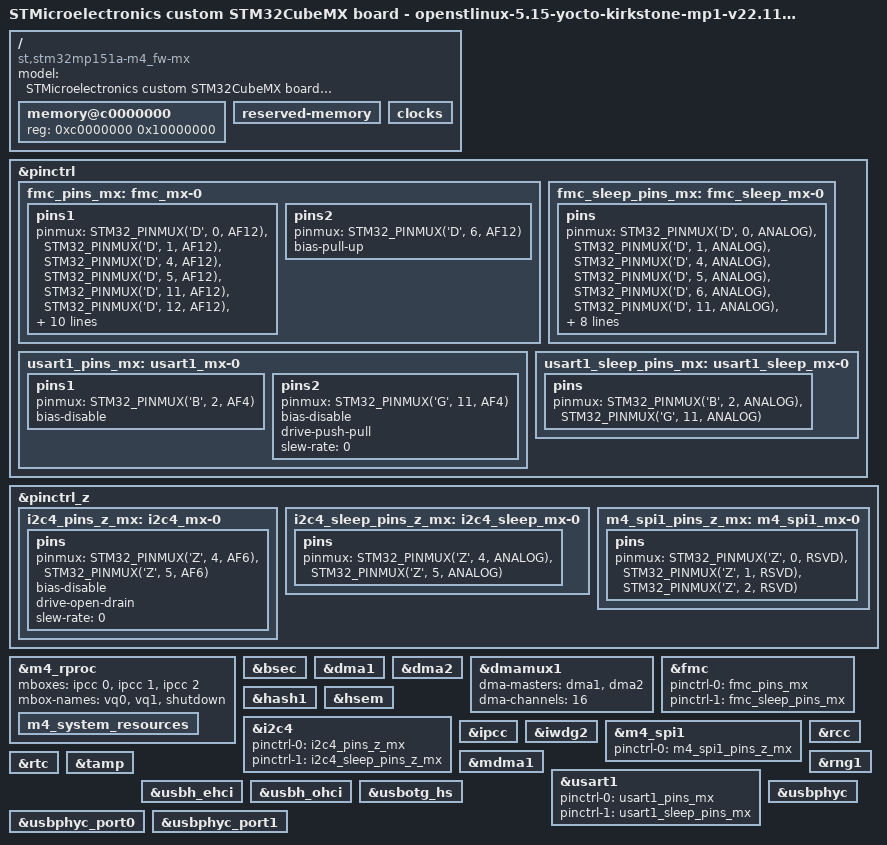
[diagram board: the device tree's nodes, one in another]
/* SPDX-License-Identifier: (GPL-2.0+ OR BSD-3-Clause) */
/*
 * Copyright (C) STMicroelectronics 2023 - All Rights Reserved
 * Author: STM32CubeMX code generation for STMicroelectronics.
 */

/* For more information on Device Tree configuration, please refer to
 * https://wiki.st.com/stm32mpu/wiki/Category:Device_tree_configuration
 */

/dts-v1/;
#include <dt-bindings/pinctrl/stm32-pinfunc.h>

#include "stm32mp151.dtsi"
#include "stm32mp15xa.dtsi"
#include "stm32mp15xxac-pinctrl.dtsi"
#include "stm32mp15-m4-srm.dtsi"

/* USER CODE BEGIN includes */
/* USER CODE END includes */

/ {
	model = "STMicroelectronics custom STM32CubeMX board - openstlinux-5.15-yocto-kirkstone-mp1-v22.11.23";
	compatible = "st,stm32mp151a-m4_fw-mx", "st,stm32mp151";

	memory@c0000000 {
		device_type = "memory";
		reg = <0xc0000000 0x10000000>;

		/* USER CODE BEGIN memory */
		/* USER CODE END memory */
	};

	reserved-memory {
		#address-cells = <1>;
		#size-cells = <1>;
		ranges;

		/* USER CODE BEGIN reserved-memory */
		/* USER CODE END reserved-memory */
	};

	/* USER CODE BEGIN root */
	/* USER CODE END root */

	clocks {

		/* USER CODE BEGIN clocks */
		/* USER CODE END clocks */
	};

}; /*root*/

&pinctrl {

	fmc_pins_mx: fmc_mx-0 {
		pins1 {
			pinmux = <STM32_PINMUX('D', 0, AF12)>, /* FMC_D2 */
					 <STM32_PINMUX('D', 1, AF12)>, /* FMC_D3 */
					 <STM32_PINMUX('D', 4, AF12)>, /* FMC_NOE */
					 <STM32_PINMUX('D', 5, AF12)>, /* FMC_NWE */
					 <STM32_PINMUX('D', 11, AF12)>, /* FMC_CLE */
					 <STM32_PINMUX('D', 12, AF12)>, /* FMC_ALE */
					 <STM32_PINMUX('D', 14, AF12)>, /* FMC_D0 */
					 <STM32_PINMUX('D', 15, AF12)>, /* FMC_D1 */
					 <STM32_PINMUX('E', 7, AF12)>, /* FMC_D4 */
					 <STM32_PINMUX('E', 8, AF12)>, /* FMC_D5 */
					 <STM32_PINMUX('E', 9, AF12)>, /* FMC_D6 */
					 <STM32_PINMUX('E', 10, AF12)>, /* FMC_D7 */
					 <STM32_PINMUX('G', 9, AF12)>; /* FMC_NCE */
			bias-disable;
			drive-push-pull;
			slew-rate = <1>;
		};
		pins2 {
			pinmux = <STM32_PINMUX('D', 6, AF12)>; /* FMC_NWAIT */
			bias-pull-up;
		};
	};

	fmc_sleep_pins_mx: fmc_sleep_mx-0 {
		pins {
			pinmux = <STM32_PINMUX('D', 0, ANALOG)>, /* FMC_D2 */
					 <STM32_PINMUX('D', 1, ANALOG)>, /* FMC_D3 */
					 <STM32_PINMUX('D', 4, ANALOG)>, /* FMC_NOE */
					 <STM32_PINMUX('D', 5, ANALOG)>, /* FMC_NWE */
					 <STM32_PINMUX('D', 6, ANALOG)>, /* FMC_NWAIT */
					 <STM32_PINMUX('D', 11, ANALOG)>, /* FMC_CLE */
					 <STM32_PINMUX('D', 12, ANALOG)>, /* FMC_ALE */
					 <STM32_PINMUX('D', 14, ANALOG)>, /* FMC_D0 */
					 <STM32_PINMUX('D', 15, ANALOG)>, /* FMC_D1 */
					 <STM32_PINMUX('E', 7, ANALOG)>, /* FMC_D4 */
					 <STM32_PINMUX('E', 8, ANALOG)>, /* FMC_D5 */
					 <STM32_PINMUX('E', 9, ANALOG)>, /* FMC_D6 */
					 <STM32_PINMUX('E', 10, ANALOG)>, /* FMC_D7 */
					 <STM32_PINMUX('G', 9, ANALOG)>; /* FMC_NCE */
		};
	};

	usart1_pins_mx: usart1_mx-0 {
		pins1 {
			pinmux = <STM32_PINMUX('B', 2, AF4)>; /* USART1_RX */
			bias-disable;
		};
		pins2 {
			pinmux = <STM32_PINMUX('G', 11, AF4)>; /* USART1_TX */
			bias-disable;
			drive-push-pull;
			slew-rate = <0>;
		};
	};

	usart1_sleep_pins_mx: usart1_sleep_mx-0 {
		pins {
			pinmux = <STM32_PINMUX('B', 2, ANALOG)>, /* USART1_RX */
					 <STM32_PINMUX('G', 11, ANALOG)>; /* USART1_TX */
		};
	};

	/* USER CODE BEGIN pinctrl */
	/* USER CODE END pinctrl */
};

&pinctrl_z {

	i2c4_pins_z_mx: i2c4_mx-0 {
		pins {
			pinmux = <STM32_PINMUX('Z', 4, AF6)>, /* I2C4_SCL */
					 <STM32_PINMUX('Z', 5, AF6)>; /* I2C4_SDA */
			bias-disable;
			drive-open-drain;
			slew-rate = <0>;
		};
	};

	i2c4_sleep_pins_z_mx: i2c4_sleep_mx-0 {
		pins {
			pinmux = <STM32_PINMUX('Z', 4, ANALOG)>, /* I2C4_SCL */
					 <STM32_PINMUX('Z', 5, ANALOG)>; /* I2C4_SDA */
		};
	};

	m4_spi1_pins_z_mx: m4_spi1_mx-0 {
		pins {
			pinmux = <STM32_PINMUX('Z', 0, RSVD)>, /* SPI1_SCK */
					 <STM32_PINMUX('Z', 1, RSVD)>, /* SPI1_MISO */
					 <STM32_PINMUX('Z', 2, RSVD)>; /* SPI1_MOSI */
		};
	};

	/* USER CODE BEGIN pinctrl_z */
	/* USER CODE END pinctrl_z */
};

&m4_rproc{
	/*Restriction: "memory-region" property is not managed - please to use User-Section if needed*/
	mboxes = <&ipcc 0>, <&ipcc 1>, <&ipcc 2>;
	mbox-names = "vq0", "vq1", "shutdown";
	status = "okay";

	/* USER CODE BEGIN m4_rproc */
	/* USER CODE END m4_rproc */

	m4_system_resources{
		status = "okay";

		/* USER CODE BEGIN m4_system_resources */
		/* USER CODE END m4_system_resources */
	};
};

&bsec{
	status = "okay";

	/* USER CODE BEGIN bsec */
	/* USER CODE END bsec */
};

&dma1{
	status = "okay";

	/* USER CODE BEGIN dma1 */
	/* USER CODE END dma1 */
};

&dma2{
	status = "okay";

	/* USER CODE BEGIN dma2 */
	/* USER CODE END dma2 */
};

&dmamux1{
	status = "okay";

	dma-masters = <&dma1 &dma2>;
	dma-channels = <16>;

	/* USER CODE BEGIN dmamux1 */
	/* USER CODE END dmamux1 */
};

&fmc{
	pinctrl-names = "default", "sleep";
	pinctrl-0 = <&fmc_pins_mx>;
	pinctrl-1 = <&fmc_sleep_pins_mx>;
	status = "okay";

	/* USER CODE BEGIN fmc */
	/* USER CODE END fmc */
};

&hash1{
	status = "okay";

	/* USER CODE BEGIN hash1 */
	/* USER CODE END hash1 */
};

&hsem{
	status = "okay";

	/* USER CODE BEGIN hsem */
	/* USER CODE END hsem */
};

&i2c4{
	pinctrl-names = "default", "sleep";
	pinctrl-0 = <&i2c4_pins_z_mx>;
	pinctrl-1 = <&i2c4_sleep_pins_z_mx>;
	status = "okay";

	/* USER CODE BEGIN i2c4 */
	/* USER CODE END i2c4 */
};

&ipcc{
	status = "okay";

	/* USER CODE BEGIN ipcc */
	/* USER CODE END ipcc */
};

&iwdg2{
	status = "okay";

	/* USER CODE BEGIN iwdg2 */
	/* USER CODE END iwdg2 */
};

&m4_spi1{
	pinctrl-names = "default";
	pinctrl-0 = <&m4_spi1_pins_z_mx>;
	status = "okay";

	/* USER CODE BEGIN m4_spi1 */
	/* USER CODE END m4_spi1 */
};

&mdma1{
	status = "okay";

	/* USER CODE BEGIN mdma1 */
	/* USER CODE END mdma1 */
};

&rcc{
	status = "okay";

	/* USER CODE BEGIN rcc */
	/* USER CODE END rcc */
};

&rng1{
	status = "okay";

	/* USER CODE BEGIN rng1 */
	/* USER CODE END rng1 */
};

&rtc{
	status = "okay";

	/* USER CODE BEGIN rtc */
	/* USER CODE END rtc */
};

&tamp{
	status = "okay";

	/* USER CODE BEGIN tamp */
	/* USER CODE END tamp */
};

&usart1{
	pinctrl-names = "default", "sleep";
	pinctrl-0 = <&usart1_pins_mx>;
	pinctrl-1 = <&usart1_sleep_pins_mx>;
	status = "okay";

	/* USER CODE BEGIN usart1 */
	/* USER CODE END usart1 */
};

&usbh_ehci{
	status = "okay";

	/* USER CODE BEGIN usbh_ehci */
	/* USER CODE END usbh_ehci */
};

&usbh_ohci{
	status = "okay";

	/* USER CODE BEGIN usbh_ohci */
	/* USER CODE END usbh_ohci */
};

&usbotg_hs{
	status = "okay";

	/* USER CODE BEGIN usbotg_hs */
	/* USER CODE END usbotg_hs */
};

&usbphyc{
	status = "okay";

	/* USER CODE BEGIN usbphyc */
	/* USER CODE END usbphyc */
};

&usbphyc_port0{
	status = "okay";

	/* USER CODE BEGIN usbphyc_port0 */
	/* USER CODE END usbphyc_port0 */
};

&usbphyc_port1{
	status = "okay";

	/* USER CODE BEGIN usbphyc_port1 */
	/* USER CODE END usbphyc_port1 */
};

/* USER CODE BEGIN addons */
/* USER CODE END addons */

